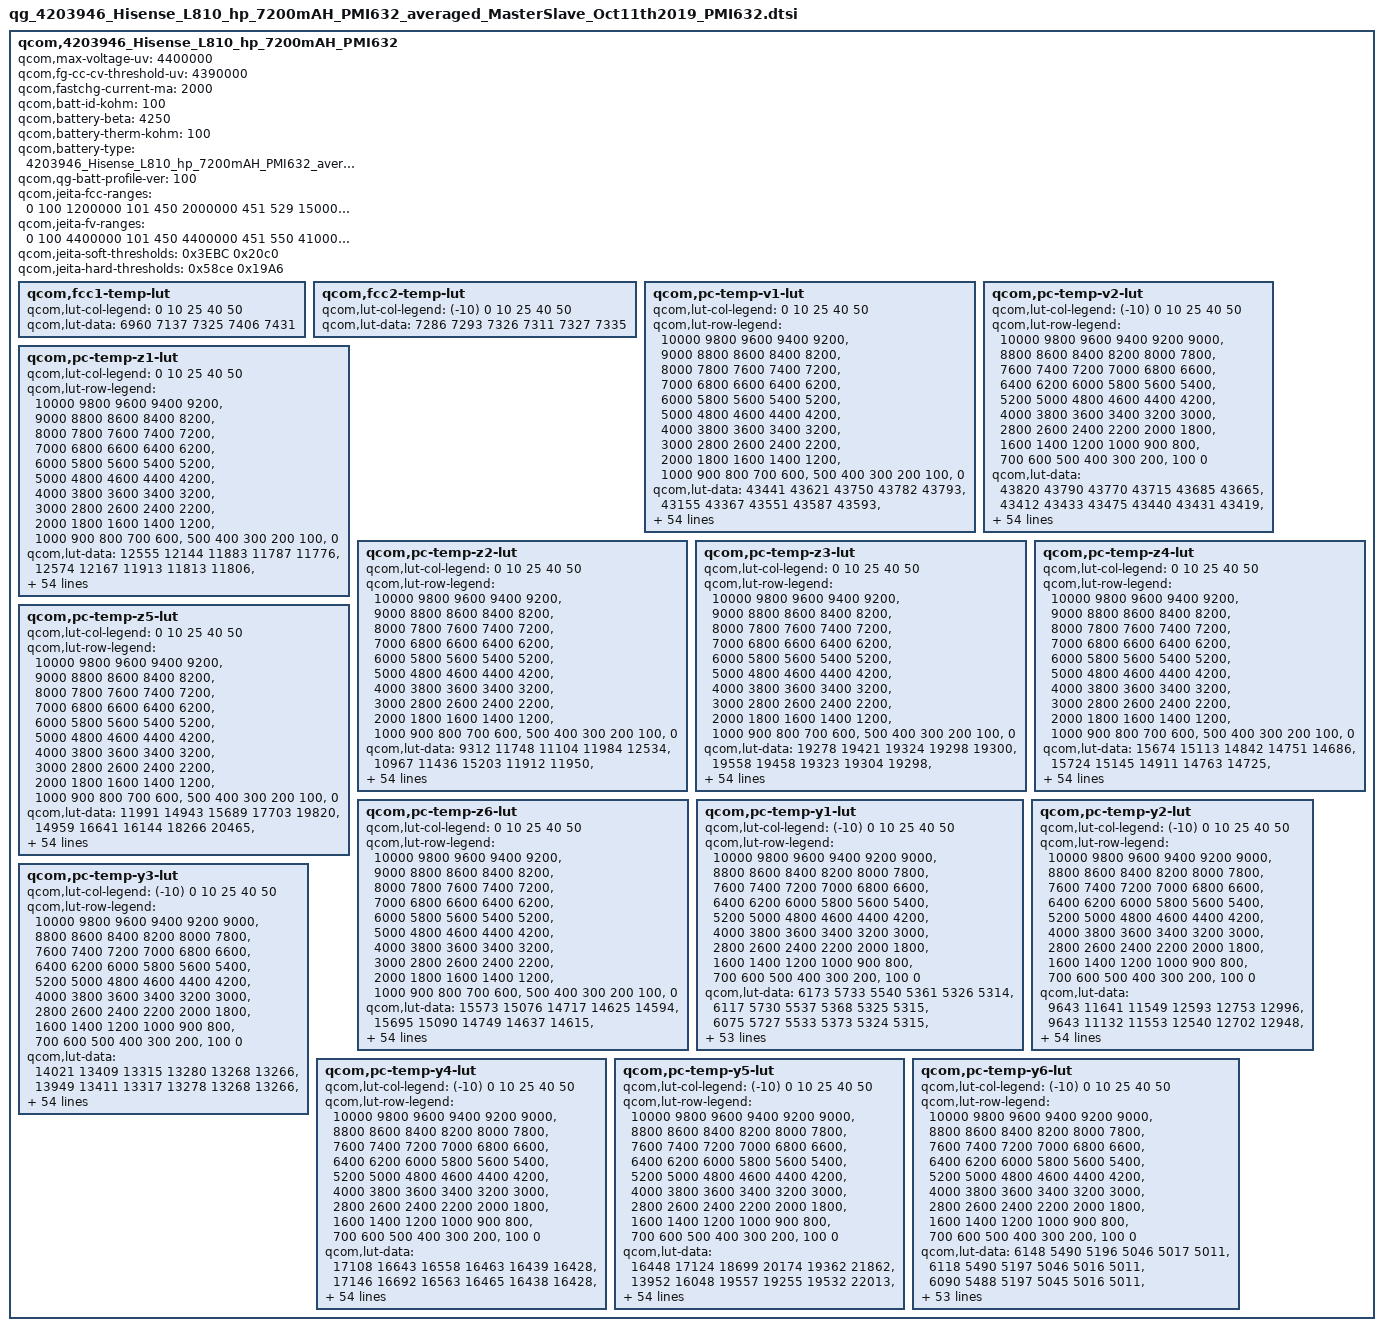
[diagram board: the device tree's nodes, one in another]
qcom,4203946_Hisense_L810_hp_7200mAH_PMI632 {
    /* 4203946_Hisense_L810_hp_7200mAH_PMI632_averaged_MasterSlave_Oct11th2019 */
    qcom,max-voltage-uv = <4400000>;
    qcom,fg-cc-cv-threshold-uv = <4390000>;
    qcom,fastchg-current-ma = <2000>;
    qcom,batt-id-kohm = <100>;
    qcom,battery-beta = <4250>;
    qcom,battery-therm-kohm = <100>;
    qcom,battery-type = "4203946_Hisense_L810_hp_7200mAH_PMI632_averaged_MasterSlave_Oct11th2019";
    qcom,qg-batt-profile-ver = <100>;

	qcom,jeita-fcc-ranges = <0  100   1200000
				 101 450  2000000
				 451 529  1500000>;
	qcom,jeita-fv-ranges =  <0  100  4400000
				 101 450  4400000
				 451 550  4100000>;
	/* COOL = 10 DegC, WARM = 45 DegC */
	qcom,jeita-soft-thresholds = <0x3EBC 0x20c0>;
	/* COLD = 0 DegC, HOT = 53 DegC */
	qcom,jeita-hard-thresholds = <0x58ce 0x19A6>;
	qcom,fcc1-temp-lut {
		qcom,lut-col-legend = <0 10 25 40 50>;
		qcom,lut-data = <6960 7137 7325 7406 7431>;
	};

	qcom,fcc2-temp-lut {
		qcom,lut-col-legend = <(-10) 0 10 25 40 50>;
		qcom,lut-data = <7286 7293 7326 7311 7327 7335>;
	};

	qcom,pc-temp-v1-lut {
		qcom,lut-col-legend = <0 10 25 40 50>;
		qcom,lut-row-legend = <10000 9800 9600 9400 9200>,
			<9000 8800 8600 8400 8200>,
			<8000 7800 7600 7400 7200>,
			<7000 6800 6600 6400 6200>,
			<6000 5800 5600 5400 5200>,
			<5000 4800 4600 4400 4200>,
			<4000 3800 3600 3400 3200>,
			<3000 2800 2600 2400 2200>,
			<2000 1800 1600 1400 1200>,
			<1000 900 800 700 600>,
			<500 400 300 200 100>,
			<0>;
		qcom,lut-data = <43441 43621 43750 43782 43793>,
			<43155 43367 43551 43587 43593>,
			<42911 43120 43325 43374 43386>,
			<42683 42882 43083 43147 43166>,
			<42459 42650 42845 42917 42941>,
			<42242 42424 42606 42684 42711>,
			<42030 42201 42372 42450 42478>,
			<41822 41985 42144 42216 42246>,
			<41620 41772 41919 41985 42015>,
			<41432 41564 41695 41756 41787>,
			<41272 41372 41473 41529 41562>,
			<41098 41207 41267 41308 41342>,
			<40859 41029 41088 41094 41123>,
			<40566 40786 40902 40887 40909>,
			<40305 40495 40657 40680 40702>,
			<40085 40251 40384 40472 40503>,
			<39896 40053 40176 40276 40311>,
			<39755 39887 40024 40100 40129>,
			<39645 39760 39882 39934 39954>,
			<39539 39656 39733 39765 39779>,
			<39425 39537 39578 39596 39607>,
			<39311 39391 39375 39408 39422>,
			<39199 39226 39092 39161 39193>,
			<39087 39029 38865 38926 38965>,
			<38979 38801 38741 38784 38810>,
			<38872 38640 38647 38681 38693>,
			<38767 38537 38563 38581 38584>,
			<38667 38461 38490 38480 38476>,
			<38568 38409 38419 38387 38377>,
			<38479 38371 38345 38301 38290>,
			<38414 38334 38276 38224 38212>,
			<38362 38298 38215 38156 38141>,
			<38317 38263 38161 38099 38078>,
			<38279 38229 38113 38043 38017>,
			<38245 38197 38072 37992 37960>,
			<38209 38161 38033 37942 37905>,
			<38174 38121 37993 37890 37843>,
			<38132 38075 37952 37839 37774>,
			<38072 38008 37894 37774 37698>,
			<37994 37910 37799 37686 37613>,
			<37904 37798 37685 37579 37516>,
			<37794 37672 37563 37462 37401>,
			<37663 37532 37426 37327 37266>,
			<37501 37375 37267 37170 37112>,
			<37354 37244 37135 37039 36979>,
			<37255 37171 37061 36970 36911>,
			<37220 37145 37045 36954 36894>,
			<37194 37126 37028 36941 36881>,
			<37165 37102 37015 36921 36861>,
			<37093 37037 36941 36835 36767>,
			<36814 36742 36647 36530 36458>,
			<36356 36291 36199 36078 36010>,
			<35774 35708 35619 35493 35431>,
			<34986 34919 34826 34697 34644>,
			<33744 33680 33595 33458 33433>,
			<30000 30000 30000 30000 30000>;
	};

	qcom,pc-temp-v2-lut {
		qcom,lut-col-legend = <(-10) 0 10 25 40 50>;
		qcom,lut-row-legend = <10000 9800 9600 9400 9200 9000>,
			<8800 8600 8400 8200 8000 7800>,
			<7600 7400 7200 7000 6800 6600>,
			<6400 6200 6000 5800 5600 5400>,
			<5200 5000 4800 4600 4400 4200>,
			<4000 3800 3600 3400 3200 3000>,
			<2800 2600 2400 2200 2000 1800>,
			<1600 1400 1200 1000 900 800>,
			<700 600 500 400 300 200>,
			<100 0>;
		qcom,lut-data = <43820 43790 43770 43715 43685 43665>,
			<43412 43433 43475 43440 43431 43419>,
			<43044 43106 43198 43178 43183 43178>,
			<42719 42813 42937 42929 42943 42941>,
			<42431 42548 42693 42693 42709 42709>,
			<42172 42299 42455 42461 42477 42477>,
			<41942 42065 42220 42230 42246 42245>,
			<41730 41838 41990 42002 42017 42015>,
			<41516 41598 41767 41780 41790 41794>,
			<41297 41344 41549 41561 41566 41580>,
			<41132 41152 41339 41344 41346 41366>,
			<41044 41048 41137 41126 41130 41148>,
			<40954 40947 40940 40912 40919 40934>,
			<40668 40725 40751 40719 40716 40729>,
			<40057 40339 40566 40538 40518 40529>,
			<39633 40013 40344 40339 40326 40335>,
			<39446 39783 40039 40101 40136 40148>,
			<39299 39582 39744 39874 39952 39965>,
			<39128 39391 39546 39712 39780 39793>,
			<38952 39211 39385 39578 39613 39624>,
			<38785 39031 39214 39406 39416 39426>,
			<38614 38845 39023 39152 39163 39174>,
			<38468 38670 38846 38910 38931 38946>,
			<38366 38508 38698 38749 38770 38786>,
			<38287 38357 38565 38618 38637 38652>,
			<38218 38246 38447 38501 38518 38531>,
			<38158 38163 38341 38396 38412 38423>,
			<38103 38097 38243 38301 38315 38324>,
			<38049 38042 38153 38213 38225 38233>,
			<37998 37997 38070 38131 38143 38148>,
			<37948 37952 37992 38055 38070 38071>,
			<37900 37908 37915 37983 38001 37999>,
			<37850 37865 37852 37914 37935 37930>,
			<37796 37822 37808 37850 37870 37867>,
			<37740 37779 37770 37788 37803 37802>,
			<37680 37731 37728 37728 37719 37708>,
			<37616 37679 37683 37670 37616 37582>,
			<37548 37621 37634 37607 37519 37470>,
			<37478 37552 37578 37536 37439 37383>,
			<37406 37475 37512 37458 37360 37300>,
			<37333 37386 37431 37370 37274 37214>,
			<37259 37284 37327 37269 37180 37122>,
			<37185 37177 37195 37156 37069 37011>,
			<37113 37070 37059 37026 36936 36876>,
			<37030 36972 36954 36901 36830 36776>,
			<36936 36882 36887 36871 36809 36755>,
			<36879 36832 36859 36860 36798 36742>,
			<36812 36774 36824 36841 36778 36724>,
			<36731 36700 36767 36806 36735 36683>,
			<36595 36588 36657 36692 36586 36522>,
			<36366 36363 36396 36374 36216 36155>,
			<35982 35965 35927 35874 35705 35646>,
			<35410 35362 35293 35233 35038 34986>,
			<34562 34526 34415 34363 34096 34062>,
			<33209 33189 33050 32998 32752 32744>,
			<28901 27920 27872 28105 28114 28828>;
	};

	qcom,pc-temp-z1-lut {
		qcom,lut-col-legend = <0 10 25 40 50>;
		qcom,lut-row-legend = <10000 9800 9600 9400 9200>,
			<9000 8800 8600 8400 8200>,
			<8000 7800 7600 7400 7200>,
			<7000 6800 6600 6400 6200>,
			<6000 5800 5600 5400 5200>,
			<5000 4800 4600 4400 4200>,
			<4000 3800 3600 3400 3200>,
			<3000 2800 2600 2400 2200>,
			<2000 1800 1600 1400 1200>,
			<1000 900 800 700 600>,
			<500 400 300 200 100>,
			<0>;
		qcom,lut-data = <12555 12144 11883 11787 11776>,
			<12574 12167 11913 11813 11806>,
			<12597 12180 11921 11823 11816>,
			<12618 12184 11925 11826 11820>,
			<12618 12187 11925 11828 11824>,
			<12604 12190 11924 11831 11827>,
			<12596 12198 11925 11833 11831>,
			<12599 12204 11926 11836 11836>,
			<12602 12203 11929 11840 11840>,
			<12607 12198 11931 11843 11846>,
			<12618 12198 11935 11849 11853>,
			<12626 12207 11939 11854 11860>,
			<12619 12214 11947 11859 11864>,
			<12595 12210 11953 11862 11867>,
			<12580 12198 11948 11863 11868>,
			<12581 12191 11938 11861 11868>,
			<12586 12187 11935 11860 11868>,
			<12587 12185 11939 11861 11869>,
			<12587 12189 11943 11862 11870>,
			<12587 12197 11946 11863 11871>,
			<12593 12200 11949 11865 11871>,
			<12601 12202 11951 11866 11872>,
			<12606 12204 11954 11867 11872>,
			<12606 12204 11956 11867 11873>,
			<12605 12204 11957 11869 11874>,
			<12598 12204 11959 11870 11876>,
			<12586 12204 11960 11873 11878>,
			<12581 12205 11963 11875 11880>,
			<12580 12207 11965 11878 11882>,
			<12581 12212 11969 11880 11883>,
			<12580 12215 11973 11882 11885>,
			<12578 12214 11975 11883 11886>,
			<12578 12214 11975 11885 11888>,
			<12593 12215 11976 11887 11890>,
			<12613 12219 11980 11889 11891>,
			<12615 12225 11984 11891 11892>,
			<12607 12239 11986 11892 11894>,
			<12601 12253 11987 11894 11895>,
			<12601 12254 11989 11896 11896>,
			<12602 12250 11993 11897 11898>,
			<12604 12247 11997 11898 11899>,
			<12603 12246 11997 11901 11900>,
			<12610 12249 11995 11904 11902>,
			<12630 12264 11998 11905 11903>,
			<12633 12266 12003 11907 11904>,
			<12624 12252 12007 11910 11905>,
			<12620 12247 12003 11909 11906>,
			<12640 12263 12000 11911 11906>,
			<12595 12259 12008 11914 11908>,
			<12615 12247 12003 11916 11910>,
			<12620 12262 12011 11918 11912>,
			<12625 12266 12014 11921 11916>,
			<12633 12272 12025 11928 11921>,
			<12656 12322 12033 11937 11929>,
			<12656 12322 12033 11937 11929>,
			<12656 12322 12033 11937 11929>;
	};

	qcom,pc-temp-z2-lut {
		qcom,lut-col-legend = <0 10 25 40 50>;
		qcom,lut-row-legend = <10000 9800 9600 9400 9200>,
			<9000 8800 8600 8400 8200>,
			<8000 7800 7600 7400 7200>,
			<7000 6800 6600 6400 6200>,
			<6000 5800 5600 5400 5200>,
			<5000 4800 4600 4400 4200>,
			<4000 3800 3600 3400 3200>,
			<3000 2800 2600 2400 2200>,
			<2000 1800 1600 1400 1200>,
			<1000 900 800 700 600>,
			<500 400 300 200 100>,
			<0>;
		qcom,lut-data = <9312 11748 11104 11984 12534>,
			<10967 11436 15203 11912 11950>,
			<11025 11278 14279 12211 12062>,
			<11051 11257 13166 13397 12060>,
			<11082 11233 12801 13872 12079>,
			<11113 11208 12586 13539 12702>,
			<11138 11184 12364 13147 13532>,
			<11162 11161 12076 12987 13595>,
			<11182 11139 11887 12883 13421>,
			<11187 11120 11915 12823 13257>,
			<11182 11117 12006 12777 13067>,
			<11171 11132 12046 12728 12918>,
			<11100 11147 12057 12655 12919>,
			<10940 11130 12070 12569 12952>,
			<10866 11090 12129 12558 12911>,
			<10863 11079 12224 12633 12401>,
			<10864 11116 12217 12683 12006>,
			<10875 11174 11960 12346 12021>,
			<10907 11242 11776 11907 12045>,
			<10925 11323 11769 11893 12064>,
			<10915 11350 11759 12057 12096>,
			<10897 11341 11734 12141 12112>,
			<10887 11325 11671 12005 12074>,
			<10878 11306 11633 11841 12022>,
			<10874 11282 11633 11843 12060>,
			<10878 11274 11636 11911 12218>,
			<10888 11306 11674 11996 12287>,
			<10899 11346 11826 12132 12269>,
			<10915 11358 11909 12227 12230>,
			<10932 11364 11864 12159 12087>,
			<10944 11368 11804 12015 11825>,
			<10953 11371 11788 11984 11751>,
			<10964 11375 11782 12028 11770>,
			<10976 11381 11781 12091 11804>,
			<10991 11393 11808 12174 11895>,
			<11013 11404 11848 12274 12057>,
			<11047 11412 11879 12355 12261>,
			<11078 11422 11909 12427 12582>,
			<11103 11438 11950 12492 12733>,
			<11124 11468 12022 12565 12725>,
			<11070 11490 12076 12616 12706>,
			<10502 11497 12075 12597 12620>,
			<10163 11506 12064 12545 12448>,
			<10078 11532 12076 12550 12371>,
			<10489 11706 12155 12550 12344>,
			<10774 11960 12212 12361 12420>,
			<10928 11844 12182 12326 12319>,
			<10767 11717 12132 12269 12324>,
			<10818 11856 12228 12311 12489>,
			<10975 11847 12355 12614 12569>,
			<10719 11762 12439 12532 12181>,
			<10352 11553 12416 12358 12002>,
			<9961 11353 12444 12201 11921>,
			<9733 11108 12268 12014 11772>,
			<9733 11108 12268 12014 11772>,
			<9733 11108 12268 12014 11772>;
	};

	qcom,pc-temp-z3-lut {
		qcom,lut-col-legend = <0 10 25 40 50>;
		qcom,lut-row-legend = <10000 9800 9600 9400 9200>,
			<9000 8800 8600 8400 8200>,
			<8000 7800 7600 7400 7200>,
			<7000 6800 6600 6400 6200>,
			<6000 5800 5600 5400 5200>,
			<5000 4800 4600 4400 4200>,
			<4000 3800 3600 3400 3200>,
			<3000 2800 2600 2400 2200>,
			<2000 1800 1600 1400 1200>,
			<1000 900 800 700 600>,
			<500 400 300 200 100>,
			<0>;
		qcom,lut-data = <19278 19421 19324 19298 19300>,
			<19558 19458 19323 19304 19298>,
			<19596 19482 19342 19317 19306>,
			<19613 19491 19363 19325 19310>,
			<19613 19500 19376 19330 19312>,
			<19601 19501 19386 19334 19318>,
			<19590 19499 19394 19338 19325>,
			<19583 19496 19400 19341 19328>,
			<19574 19494 19403 19343 19330>,
			<19565 19492 19401 19345 19330>,
			<19553 19488 19395 19345 19325>,
			<19544 19476 19392 19345 19320>,
			<19564 19465 19391 19339 19319>,
			<19617 19471 19390 19330 19318>,
			<19640 19485 19388 19328 19316>,
			<19629 19489 19385 19329 19306>,
			<19610 19477 19379 19330 19298>,
			<19590 19459 19362 19322 19297>,
			<19562 19442 19350 19312 19296>,
			<19548 19424 19352 19311 19297>,
			<19550 19420 19357 19315 19300>,
			<19555 19436 19362 19318 19303>,
			<19559 19456 19370 19318 19300>,
			<19565 19465 19374 19317 19297>,
			<19570 19472 19369 19313 19297>,
			<19573 19474 19362 19307 19298>,
			<19577 19474 19359 19305 19300>,
			<19582 19473 19357 19320 19314>,
			<19587 19471 19356 19334 19327>,
			<19590 19466 19367 19336 19324>,
			<19588 19461 19380 19337 19316>,
			<19580 19457 19381 19336 19312>,
			<19570 19453 19379 19332 19311>,
			<19559 19450 19376 19328 19310>,
			<19547 19447 19372 19325 19307>,
			<19535 19446 19369 19323 19305>,
			<19519 19445 19366 19322 19305>,
			<19508 19445 19365 19322 19307>,
			<19503 19444 19363 19321 19308>,
			<19500 19442 19361 19321 19308>,
			<19477 19441 19360 19320 19306>,
			<19329 19438 19358 19317 19304>,
			<19263 19435 19356 19314 19300>,
			<19264 19427 19355 19315 19300>,
			<19261 19404 19349 19314 19301>,
			<19260 19354 19341 19307 19296>,
			<19259 19329 19334 19302 19294>,
			<19260 19304 19335 19301 19293>,
			<19260 19296 19305 19300 19290>,
			<19259 19295 19321 19292 19290>,
			<19260 19309 19305 19293 19298>,
			<19261 19306 19304 19297 19299>,
			<19264 19307 19294 19301 19300>,
			<19267 19301 19295 19303 19306>,
			<19267 19301 19295 19303 19306>,
			<19267 19301 19295 19303 19306>;
	};

	qcom,pc-temp-z4-lut {
		qcom,lut-col-legend = <0 10 25 40 50>;
		qcom,lut-row-legend = <10000 9800 9600 9400 9200>,
			<9000 8800 8600 8400 8200>,
			<8000 7800 7600 7400 7200>,
			<7000 6800 6600 6400 6200>,
			<6000 5800 5600 5400 5200>,
			<5000 4800 4600 4400 4200>,
			<4000 3800 3600 3400 3200>,
			<3000 2800 2600 2400 2200>,
			<2000 1800 1600 1400 1200>,
			<1000 900 800 700 600>,
			<500 400 300 200 100>,
			<0>;
		qcom,lut-data = <15674 15113 14842 14751 14686>,
			<15724 15145 14911 14763 14725>,
			<15641 15143 14893 14780 14744>,
			<15501 15092 14860 14765 14737>,
			<15400 15008 14829 14749 14728>,
			<15318 14947 14795 14733 14713>,
			<15249 14903 14765 14717 14696>,
			<15193 14866 14735 14703 14682>,
			<15146 14834 14713 14689 14671>,
			<15105 14808 14702 14676 14663>,
			<15071 14788 14695 14663 14658>,
			<15038 14774 14686 14654 14653>,
			<14994 14763 14671 14652 14646>,
			<14945 14752 14660 14650 14638>,
			<14911 14743 14660 14647 14634>,
			<14891 14733 14661 14639 14639>,
			<14877 14724 14662 14633 14642>,
			<14866 14717 14661 14634 14638>,
			<14855 14714 14659 14637 14632>,
			<14844 14712 14656 14638 14631>,
			<14824 14708 14653 14638 14632>,
			<14801 14696 14662 14641 14635>,
			<14783 14684 14723 14685 14672>,
			<14768 14701 14763 14736 14720>,
			<14756 14751 14763 14739 14724>,
			<14746 14772 14762 14737 14716>,
			<14738 14771 14758 14731 14704>,
			<14734 14767 14746 14706 14679>,
			<14733 14759 14729 14678 14655>,
			<14732 14743 14705 14664 14650>,
			<14732 14729 14682 14654 14647>,
			<14732 14718 14672 14648 14644>,
			<14732 14709 14667 14644 14638>,
			<14733 14700 14665 14642 14634>,
			<14734 14693 14664 14644 14636>,
			<14736 14687 14664 14647 14640>,
			<14741 14682 14664 14650 14645>,
			<14744 14679 14665 14654 14652>,
			<14742 14680 14666 14658 14655>,
			<14738 14684 14673 14661 14655>,
			<14753 14686 14678 14663 14655>,
			<14906 14684 14677 14662 14654>,
			<14974 14682 14673 14661 14653>,
			<14957 14682 14672 14661 14655>,
			<14889 14674 14664 14659 14654>,
			<14868 14692 14643 14643 14639>,
			<14865 14715 14639 14637 14632>,
			<14860 14738 14630 14626 14619>,
			<14855 14742 14656 14620 14615>,
			<14849 14741 14643 14637 14625>,
			<14856 14737 14675 14647 14625>,
			<14867 14748 14680 14645 14626>,
			<14877 14752 14692 14642 14625>,
			<14888 14764 14693 14640 14620>,
			<14888 14764 14693 14640 14620>,
			<14888 14764 14693 14640 14620>;
	};

	qcom,pc-temp-z5-lut {
		qcom,lut-col-legend = <0 10 25 40 50>;
		qcom,lut-row-legend = <10000 9800 9600 9400 9200>,
			<9000 8800 8600 8400 8200>,
			<8000 7800 7600 7400 7200>,
			<7000 6800 6600 6400 6200>,
			<6000 5800 5600 5400 5200>,
			<5000 4800 4600 4400 4200>,
			<4000 3800 3600 3400 3200>,
			<3000 2800 2600 2400 2200>,
			<2000 1800 1600 1400 1200>,
			<1000 900 800 700 600>,
			<500 400 300 200 100>,
			<0>;
		qcom,lut-data = <11991 14943 15689 17703 19820>,
			<14959 16641 16144 18266 20465>,
			<15705 17960 17236 19821 21911>,
			<16102 18847 18542 20999 22267>,
			<16250 19559 19802 21689 22637>,
			<16344 20086 21194 22292 23861>,
			<16388 20453 22508 23157 25646>,
			<16467 20836 23744 24207 27252>,
			<16583 21592 24956 25777 29132>,
			<16589 22603 26074 27728 29939>,
			<16494 22940 27162 30640 29370>,
			<16411 22582 28814 32424 28661>,
			<17519 22223 32040 31657 30251>,
			<20535 24531 34516 29983 34085>,
			<21911 29968 35035 30112 34679>,
			<21423 31805 35163 33639 28770>,
			<20682 29835 34219 36228 24087>,
			<20102 27204 29843 33202 24571>,
			<19093 25262 26654 29083 26112>,
			<18573 23399 29661 30584 28820>,
			<19197 23285 36956 36831 34759>,
			<20561 32522 44303 40023 38050>,
			<22096 45596 54317 37927 33694>,
			<24048 55773 59538 34283 26681>,
			<26401 65535 51394 29500 22867>,
			<29432 65535 37599 22351 20102>,
			<33487 64503 30959 20186 19467>,
			<37914 57847 26833 22287 24790>,
			<43885 52150 25382 25604 30209>,
			<48417 46354 29461 29628 30307>,
			<47929 42647 36392 34594 29866>,
			<44366 40429 42035 38668 30259>,
			<40622 39103 47511 42125 34724>,
			<36986 39110 50695 45013 39063>,
			<33221 39690 52348 47708 40889>,
			<30135 40538 53240 49721 42086>,
			<27012 42675 52803 49447 42167>,
			<25100 45174 51033 46729 41562>,
			<24971 46337 48762 43482 40554>,
			<25168 47143 45097 39714 37463>,
			<23991 47418 41541 35833 33261>,
			<15842 46187 39530 32820 30213>,
			<12218 44143 38059 30461 27739>,
			<12295 39681 36393 29442 25961>,
			<12675 35444 36425 28715 25807>,
			<12655 21662 38132 28802 26337>,
			<12607 17752 33168 27579 26833>,
			<12540 15081 35600 29742 31752>,
			<12522 14507 19996 32359 32809>,
			<12622 14576 25821 22902 25347>,
			<12813 15787 18590 19338 25331>,
			<12678 15132 17497 19682 24556>,
			<12565 14882 15830 20384 24833>,
			<12413 14099 15653 20815 28558>,
			<12413 14099 15653 20815 28558>,
			<12413 14099 15653 20815 28558>;
	};

	qcom,pc-temp-z6-lut {
		qcom,lut-col-legend = <0 10 25 40 50>;
		qcom,lut-row-legend = <10000 9800 9600 9400 9200>,
			<9000 8800 8600 8400 8200>,
			<8000 7800 7600 7400 7200>,
			<7000 6800 6600 6400 6200>,
			<6000 5800 5600 5400 5200>,
			<5000 4800 4600 4400 4200>,
			<4000 3800 3600 3400 3200>,
			<3000 2800 2600 2400 2200>,
			<2000 1800 1600 1400 1200>,
			<1000 900 800 700 600>,
			<500 400 300 200 100>,
			<0>;
		qcom,lut-data = <15573 15076 14717 14625 14594>,
			<15695 15090 14749 14637 14615>,
			<15650 15093 14748 14651 14628>,
			<15571 15072 14745 14650 14628>,
			<15505 15027 14739 14649 14627>,
			<15443 14990 14728 14645 14625>,
			<15390 14962 14717 14640 14622>,
			<15349 14937 14706 14635 14619>,
			<15314 14918 14697 14631 14616>,
			<15282 14901 14691 14627 14613>,
			<15250 14885 14686 14623 14610>,
			<15225 14868 14681 14619 14607>,
			<15210 14855 14675 14615 14604>,
			<15200 14849 14670 14611 14600>,
			<15187 14844 14666 14608 14597>,
			<15167 14837 14664 14605 14594>,
			<15144 14825 14659 14602 14591>,
			<15125 14813 14651 14598 14588>,
			<15108 14804 14645 14594 14585>,
			<15094 14796 14646 14594 14585>,
			<15085 14794 14647 14596 14587>,
			<15078 14798 14655 14600 14590>,
			<15073 14805 14685 14620 14606>,
			<15069 14819 14705 14640 14624>,
			<15067 14844 14703 14641 14626>,
			<15066 14854 14700 14637 14624>,
			<15064 14854 14697 14634 14621>,
			<15065 14854 14691 14631 14618>,
			<15069 14851 14686 14627 14615>,
			<15073 14843 14682 14623 14611>,
			<15073 14835 14679 14620 14606>,
			<15070 14830 14676 14616 14602>,
			<15067 14824 14674 14612 14598>,
			<15063 14821 14671 14610 14596>,
			<15060 14818 14670 14610 14597>,
			<15057 14817 14669 14610 14597>,
			<15054 14817 14669 14611 14598>,
			<15053 14817 14669 14612 14603>,
			<15053 14819 14669 14614 14605>,
			<15053 14822 14672 14615 14605>,
			<15053 14825 14675 14616 14604>,
			<15050 14826 14675 14615 14603>,
			<15047 14826 14673 14613 14601>,
			<15045 14825 14673 14614 14602>,
			<15024 14815 14669 14613 14602>,
			<15015 14801 14657 14603 14593>,
			<15016 14799 14653 14598 14589>,
			<15012 14796 14649 14592 14583>,
			<15011 14796 14646 14589 14580>,
			<15014 14798 14649 14593 14584>,
			<15024 14807 14657 14600 14590>,
			<15034 14814 14660 14602 14591>,
			<15049 14822 14663 14604 14593>,
			<15067 14833 14668 14606 14595>,
			<15067 14833 14668 14606 14595>,
			<15067 14833 14668 14606 14595>;
	};

	qcom,pc-temp-y1-lut {
		qcom,lut-col-legend = <(-10) 0 10 25 40 50>;
		qcom,lut-row-legend = <10000 9800 9600 9400 9200 9000>,
			<8800 8600 8400 8200 8000 7800>,
			<7600 7400 7200 7000 6800 6600>,
			<6400 6200 6000 5800 5600 5400>,
			<5200 5000 4800 4600 4400 4200>,
			<4000 3800 3600 3400 3200 3000>,
			<2800 2600 2400 2200 2000 1800>,
			<1600 1400 1200 1000 900 800>,
			<700 600 500 400 300 200>,
			<100 0>;
		qcom,lut-data = <6173 5733 5540 5361 5326 5314>,
			<6117 5730 5537 5368 5325 5315>,
			<6075 5727 5533 5373 5324 5315>,
			<6046 5725 5529 5377 5323 5314>,
			<6029 5724 5525 5379 5322 5314>,
			<6025 5723 5524 5380 5320 5314>,
			<6040 5724 5523 5379 5320 5313>,
			<6061 5726 5523 5377 5319 5312>,
			<6063 5725 5524 5377 5318 5311>,
			<6061 5723 5528 5374 5317 5311>,
			<6059 5722 5530 5373 5316 5311>,
			<6052 5729 5531 5374 5316 5311>,
			<6042 5739 5532 5374 5316 5311>,
			<6041 5744 5532 5374 5315 5311>,
			<6049 5749 5532 5373 5314 5311>,
			<6052 5752 5532 5373 5314 5311>,
			<6044 5760 5535 5375 5314 5311>,
			<6036 5767 5537 5377 5315 5311>,
			<6038 5765 5536 5377 5315 5311>,
			<6042 5760 5534 5376 5316 5311>,
			<6044 5756 5533 5375 5316 5312>,
			<6042 5750 5529 5375 5316 5312>,
			<6040 5744 5526 5375 5316 5312>,
			<6039 5748 5531 5377 5316 5313>,
			<6040 5757 5540 5381 5317 5313>,
			<6040 5759 5541 5382 5318 5314>,
			<6040 5751 5535 5381 5318 5314>,
			<6041 5744 5531 5381 5319 5314>,
			<6041 5744 5531 5382 5320 5315>,
			<6039 5746 5533 5384 5321 5316>,
			<6037 5745 5536 5386 5323 5317>,
			<6033 5740 5544 5387 5324 5319>,
			<6031 5736 5548 5388 5325 5320>,
			<6038 5740 5542 5390 5326 5321>,
			<6055 5747 5535 5391 5328 5321>,
			<6059 5752 5535 5392 5329 5322>,
			<6048 5757 5538 5392 5331 5323>,
			<6037 5761 5542 5393 5332 5324>,
			<6031 5755 5548 5396 5334 5325>,
			<6027 5746 5553 5400 5335 5327>,
			<6025 5747 5553 5402 5336 5328>,
			<6025 5758 5548 5404 5337 5329>,
			<6026 5756 5546 5406 5338 5330>,
			<6030 5750 5542 5408 5340 5331>,
			<6040 5761 5542 5407 5341 5332>,
			<6036 5759 5545 5407 5344 5333>,
			<6032 5760 5541 5410 5343 5333>,
			<6047 5777 5550 5408 5346 5334>,
			<6072 5762 5549 5412 5344 5334>,
			<6063 5767 5556 5415 5345 5335>,
			<6051 5773 5550 5414 5348 5337>,
			<6054 5773 5563 5416 5350 5339>,
			<6077 5777 5567 5425 5354 5342>,
			<6079 5782 5584 5431 5360 5348>,
			<6079 5782 5584 5431 5360 5348>,
			<6079 5782 5584 5431 5360 5348>;
	};

	qcom,pc-temp-y2-lut {
		qcom,lut-col-legend = <(-10) 0 10 25 40 50>;
		qcom,lut-row-legend = <10000 9800 9600 9400 9200 9000>,
			<8800 8600 8400 8200 8000 7800>,
			<7600 7400 7200 7000 6800 6600>,
			<6400 6200 6000 5800 5600 5400>,
			<5200 5000 4800 4600 4400 4200>,
			<4000 3800 3600 3400 3200 3000>,
			<2800 2600 2400 2200 2000 1800>,
			<1600 1400 1200 1000 900 800>,
			<700 600 500 400 300 200>,
			<100 0>;
		qcom,lut-data = <9643 11641 11549 12593 12753 12996>,
			<9643 11132 11553 12540 12702 12948>,
			<9643 10756 11552 12459 12615 12867>,
			<9771 10501 11545 12372 12519 12777>,
			<9928 10359 11536 12304 12443 12704>,
			<10097 10320 11524 12278 12415 12672>,
			<10331 10451 11503 12283 12419 12635>,
			<10531 10638 11483 12291 12425 12581>,
			<10432 10709 11485 12284 12426 12537>,
			<9937 10789 11500 12258 12421 12496>,
			<9682 10885 11506 12238 12419 12477>,
			<9684 11047 11494 12229 12467 12440>,
			<9687 11192 11481 12225 12520 12405>,
			<9685 11216 11568 12228 12525 12462>,
			<9679 11218 11816 12237 12525 12611>,
			<9675 11230 11907 12252 12536 12658>,
			<9674 11314 11860 12300 12601 12570>,
			<9673 11425 11815 12370 12694 12490>,
			<9673 11501 11827 12465 12828 12627>,
			<9672 11566 11865 12586 13005 12932>,
			<9672 11567 11904 12619 13039 13009>,
			<9671 11142 11950 12570 12883 12922>,
			<9671 10753 12004 12525 12758 12848>,
			<9670 10528 12070 12541 12792 12855>,
			<9670 9974 12141 12593 12857 12881>,
			<9669 9772 12187 12646 12870 12898>,
			<9668 9765 12218 12720 12878 12980>,
			<9668 9756 12240 12773 12900 13064>,
			<9667 9744 12256 12789 12982 13121>,
			<9666 9728 12272 12797 13101 13169>,
			<9666 9716 12292 12796 13169 13178>,
			<9665 9708 12321 12790 13272 13156>,
			<9665 9701 12335 12784 13319 13162>,
			<9665 9695 12289 12738 13261 13237>,
			<9664 9689 12189 12678 13191 13310>,
			<9664 9684 11912 12682 13168 13290>,
			<9664 9680 11295 12731 13103 13189>,
			<9664 9676 11042 12757 13065 13118>,
			<9663 9673 11407 12768 13027 13074>,
			<9663 9670 11774 12778 12993 13040>,
			<9663 9668 11731 12739 13032 13082>,
			<9663 9666 11595 12636 13087 13193>,
			<9663 9665 10985 12614 13130 13270>,
			<9662 9664 10209 12592 13157 13247>,
			<9662 9663 9976 12421 12926 12947>,
			<9662 9663 9852 12316 12871 12976>,
			<9662 9662 9801 12328 12868 12965>,
			<9662 9662 9754 12365 12840 12842>,
			<9662 9662 9741 12290 12794 12707>,
			<9662 9662 9746 12226 12802 12580>,
			<9662 9661 9727 12118 12819 12606>,
			<9662 9661 9707 11989 12610 12428>,
			<9661 9661 9688 11814 12365 12295>,
			<9660 9660 9677 11664 12192 12085>,
			<9660 9660 9677 11664 12192 12085>,
			<9660 9660 9677 11664 12192 12085>;
	};

	qcom,pc-temp-y3-lut {
		qcom,lut-col-legend = <(-10) 0 10 25 40 50>;
		qcom,lut-row-legend = <10000 9800 9600 9400 9200 9000>,
			<8800 8600 8400 8200 8000 7800>,
			<7600 7400 7200 7000 6800 6600>,
			<6400 6200 6000 5800 5600 5400>,
			<5200 5000 4800 4600 4400 4200>,
			<4000 3800 3600 3400 3200 3000>,
			<2800 2600 2400 2200 2000 1800>,
			<1600 1400 1200 1000 900 800>,
			<700 600 500 400 300 200>,
			<100 0>;
		qcom,lut-data = <14021 13409 13315 13280 13268 13266>,
			<13949 13411 13317 13278 13268 13266>,
			<13858 13410 13319 13277 13268 13267>,
			<13769 13408 13322 13276 13269 13267>,
			<13702 13405 13323 13275 13269 13267>,
			<13677 13404 13325 13275 13269 13268>,
			<13691 13402 13326 13276 13270 13268>,
			<13709 13401 13327 13278 13270 13269>,
			<13683 13405 13328 13280 13270 13269>,
			<13571 13414 13328 13282 13270 13269>,
			<13513 13418 13329 13284 13270 13269>,
			<13535 13391 13329 13284 13272 13269>,
			<13561 13360 13329 13284 13274 13269>,
			<13550 13361 13329 13286 13274 13269>,
			<13502 13375 13329 13288 13273 13271>,
			<13472 13381 13328 13289 13273 13272>,
			<13463 13376 13324 13289 13274 13271>,
			<13458 13368 13320 13289 13276 13271>,
			<13461 13362 13317 13289 13278 13271>,
			<13469 13356 13315 13290 13279 13273>,
			<13472 13348 13312 13290 13279 13274>,
			<13467 13328 13308 13285 13275 13270>,
			<13463 13309 13304 13280 13271 13267>,
			<13467 13306 13301 13278 13270 13266>,
			<13482 13304 13297 13277 13268 13266>,
			<13498 13300 13296 13277 13268 13266>,
			<13516 13289 13296 13277 13268 13266>,
			<13536 13281 13295 13278 13268 13266>,
			<13558 13285 13295 13279 13268 13267>,
			<13582 13295 13295 13280 13270 13267>,
			<13608 13304 13294 13280 13270 13267>,
			<13637 13311 13289 13280 13271 13267>,
			<13668 13320 13286 13280 13271 13267>,
			<13699 13333 13289 13279 13271 13268>,
			<13731 13350 13293 13279 13271 13268>,
			<13767 13369 13294 13279 13271 13268>,
			<13805 13391 13293 13280 13270 13267>,
			<13846 13417 13293 13280 13269 13266>,
			<13886 13448 13299 13279 13268 13266>,
			<13928 13485 13304 13277 13268 13266>,
			<13970 13528 13306 13276 13268 13266>,
			<14011 13578 13307 13276 13268 13266>,
			<14058 13636 13302 13278 13269 13266>,
			<14107 13701 13299 13280 13270 13266>,
			<14139 13756 13307 13279 13268 13267>,
			<14139 13780 13318 13279 13269 13267>,
			<14181 13824 13325 13282 13272 13268>,
			<14227 13873 13336 13284 13272 13270>,
			<14281 13916 13350 13289 13274 13272>,
			<14337 13954 13365 13291 13276 13270>,
			<14394 13981 13375 13290 13270 13270>,
			<14460 14026 13379 13292 13275 13270>,
			<14550 14112 13406 13295 13278 13273>,
			<14686 14241 13459 13304 13279 13274>,
			<14686 14241 13459 13304 13279 13274>,
			<14686 14241 13459 13304 13279 13274>;
	};

	qcom,pc-temp-y4-lut {
		qcom,lut-col-legend = <(-10) 0 10 25 40 50>;
		qcom,lut-row-legend = <10000 9800 9600 9400 9200 9000>,
			<8800 8600 8400 8200 8000 7800>,
			<7600 7400 7200 7000 6800 6600>,
			<6400 6200 6000 5800 5600 5400>,
			<5200 5000 4800 4600 4400 4200>,
			<4000 3800 3600 3400 3200 3000>,
			<2800 2600 2400 2200 2000 1800>,
			<1600 1400 1200 1000 900 800>,
			<700 600 500 400 300 200>,
			<100 0>;
		qcom,lut-data = <17108 16643 16558 16463 16439 16428>,
			<17146 16692 16563 16465 16438 16428>,
			<17162 16745 16571 16468 16437 16428>,
			<17162 16796 16579 16471 16437 16428>,
			<17149 16834 16585 16473 16438 16428>,
			<17127 16854 16588 16475 16438 16428>,
			<17033 16858 16589 16476 16440 16429>,
			<16923 16856 16590 16476 16442 16430>,
			<17000 16844 16593 16477 16445 16432>,
			<17362 16823 16604 16479 16449 16434>,
			<17553 16817 16614 16482 16451 16437>,
			<17555 17000 16623 16487 16453 16441>,
			<17552 17221 16633 16495 16454 16445>,
			<17440 17177 16675 16504 16459 16448>,
			<17088 16953 16756 16515 16469 16450>,
			<16921 16814 16781 16526 16478 16454>,
			<16915 16769 16712 16535 16482 16461>,
			<16910 16740 16637 16546 16488 16471>,
			<16884 16719 16618 16562 16502 16482>,
			<16822 16704 16608 16583 16521 16494>,
			<16773 16692 16590 16584 16522 16494>,
			<16736 16680 16555 16525 16484 16467>,
			<16712 16670 16528 16470 16449 16443>,
			<16705 16648 16521 16462 16443 16437>,
			<16701 16612 16516 16458 16439 16433>,
			<16699 16602 16514 16457 16439 16433>,
			<16697 16609 16513 16459 16441 16434>,
			<16696 16614 16512 16461 16444 16436>,
			<16698 16613 16509 16464 16447 16439>,
			<16703 16611 16507 16468 16452 16444>,
			<16706 16611 16505 16472 16458 16449>,
			<16709 16617 16503 16478 16466 16456>,
			<16712 16623 16502 16481 16472 16462>,
			<16716 16629 16502 16482 16477 16467>,
			<16719 16635 16503 16482 16480 16470>,
			<16721 16641 16510 16481 16475 16465>,
			<16722 16647 16529 16474 16454 16447>,
			<16723 16652 16539 16468 16443 16437>,
			<16723 16657 16539 16463 16441 16435>,
			<16724 16661 16539 16460 16441 16434>,
			<16727 16661 16543 16461 16441 16435>,
			<16740 16657 16548 16467 16442 16436>,
			<16756 16656 16562 16471 16444 16438>,
			<16777 16657 16572 16473 16443 16435>,
			<16792 16665 16569 16462 16435 16427>,
			<16773 16675 16585 16474 16445 16437>,
			<16786 16703 16607 16484 16450 16441>,
			<16810 16729 16638 16498 16457 16447>,
			<16836 16768 16676 16517 16467 16456>,
			<16845 16808 16710 16522 16456 16446>,
			<16841 16827 16707 16504 16447 16433>,
			<16821 16821 16693 16501 16446 16435>,
			<16818 16814 16712 16520 16453 16441>,
			<16851 16834 16762 16559 16485 16468>,
			<16851 16834 16762 16559 16485 16468>,
			<16851 16834 16762 16559 16485 16468>;
	};

	qcom,pc-temp-y5-lut {
		qcom,lut-col-legend = <(-10) 0 10 25 40 50>;
		qcom,lut-row-legend = <10000 9800 9600 9400 9200 9000>,
			<8800 8600 8400 8200 8000 7800>,
			<7600 7400 7200 7000 6800 6600>,
			<6400 6200 6000 5800 5600 5400>,
			<5200 5000 4800 4600 4400 4200>,
			<4000 3800 3600 3400 3200 3000>,
			<2800 2600 2400 2200 2000 1800>,
			<1600 1400 1200 1000 900 800>,
			<700 600 500 400 300 200>,
			<100 0>;
		qcom,lut-data = <16448 17124 18699 20174 19362 21862>,
			<13952 16048 19557 19255 19532 22013>,
			<12864 15593 20215 18215 19531 22079>,
			<12877 15538 20678 17241 19396 22077>,
			<13684 15663 20947 16518 19163 22025>,
			<14995 15751 21025 16234 18869 21938>,
			<19267 16184 20806 16326 18461 21629>,
			<24095 16662 20426 16521 17966 21114>,
			<23051 16314 20058 16825 17411 20551>,
			<16358 15428 19507 17528 16770 19859>,
			<12984 15020 18900 17845 16560 19110>,
			<17226 15256 17760 17395 17476 18105>,
			<22409 15803 16781 16857 18481 17361>,
			<21333 17925 16954 16756 18014 17651>,
			<15862 23005 17860 16717 16505 18557>,
			<13379 25093 19081 16710 15966 18804>,
			<13690 23602 21345 16762 16479 17711>,
			<14209 22009 23321 16912 17302 16711>,
			<14799 22178 23931 18192 18232 17187>,
			<15504 22928 24291 21108 19412 18432>,
			<15664 23011 24304 22553 20700 19247>,
			<14336 20546 23606 22802 22390 19716>,
			<12961 18194 22615 22824 23416 20140>,
			<12785 17112 21381 22229 22550 20695>,
			<12756 14924 20085 20852 20710 21223>,
			<12775 13878 19832 20470 19821 21297>,
			<12925 13172 20006 20829 19349 20780>,
			<13047 12691 20274 21395 19265 20511>,
			<13054 12871 21045 22471 20024 20953>,
			<13097 13272 22080 23832 21250 21494>,
			<13181 13444 21716 24335 22189 21449>,
			<13344 13446 18923 24490 23027 20904>,
			<13490 13456 17276 24637 23860 20631>,
			<13567 13656 18480 24851 24893 22210>,
			<13612 13959 20175 25150 25724 24173>,
			<13606 14154 20250 25842 25554 24247>,
			<13583 14422 18990 27400 24326 23686>,
			<13567 14622 18604 28155 23350 23092>,
			<13564 14675 20110 25775 21977 22537>,
			<13557 14692 21589 22190 20659 21921>,
			<13495 14658 21424 20290 20357 21038>,
			<13290 14559 20385 19048 20234 20105>,
			<13273 14442 17207 19929 21097 19877>,
			<13454 14230 14884 21379 21823 20463>,
			<13594 14076 14802 20414 21434 23743>,
			<13906 14213 14731 19415 19020 19567>,
			<14106 14037 14567 19829 20206 19035>,
			<14202 14522 14518 19097 19654 21079>,
			<14488 15223 15012 19390 20333 22122>,
			<14733 16540 16351 19830 22687 20118>,
			<14746 16715 16363 21106 18879 23067>,
			<14250 15971 15066 21584 24759 22797>,
			<13783 14449 14539 21715 27433 27288>,
			<13344 13957 14230 23661 27080 28785>,
			<13344 13957 14230 23661 27080 28785>,
			<13344 13957 14230 23661 27080 28785>;
	};

	qcom,pc-temp-y6-lut {
		qcom,lut-col-legend = <(-10) 0 10 25 40 50>;
		qcom,lut-row-legend = <10000 9800 9600 9400 9200 9000>,
			<8800 8600 8400 8200 8000 7800>,
			<7600 7400 7200 7000 6800 6600>,
			<6400 6200 6000 5800 5600 5400>,
			<5200 5000 4800 4600 4400 4200>,
			<4000 3800 3600 3400 3200 3000>,
			<2800 2600 2400 2200 2000 1800>,
			<1600 1400 1200 1000 900 800>,
			<700 600 500 400 300 200>,
			<100 0>;
		qcom,lut-data = <6148 5490 5196 5046 5017 5011>,
			<6118 5490 5197 5046 5016 5011>,
			<6090 5488 5197 5045 5016 5011>,
			<6064 5484 5196 5045 5016 5011>,
			<6041 5481 5194 5045 5017 5012>,
			<6020 5477 5193 5045 5017 5012>,
			<6002 5474 5190 5046 5018 5012>,
			<5985 5470 5187 5047 5018 5013>,
			<5969 5463 5186 5048 5019 5014>,
			<5951 5453 5187 5050 5020 5015>,
			<5944 5449 5187 5051 5021 5015>,
			<5958 5478 5188 5053 5022 5016>,
			<5974 5514 5189 5055 5024 5017>,
			<5939 5503 5198 5058 5026 5019>,
			<5813 5452 5218 5063 5028 5020>,
			<5751 5418 5224 5067 5030 5022>,
			<5748 5403 5201 5069 5033 5024>,
			<5745 5392 5176 5072 5036 5026>,
			<5739 5383 5168 5077 5041 5030>,
			<5729 5377 5164 5083 5047 5035>,
			<5720 5368 5157 5083 5047 5035>,
			<5712 5356 5144 5063 5033 5024>,
			<5707 5344 5134 5044 5020 5015>,
			<5711 5336 5130 5041 5017 5013>,
			<5723 5328 5127 5039 5016 5012>,
			<5736 5327 5127 5039 5015 5012>,
			<5750 5332 5127 5040 5016 5012>,
			<5765 5341 5128 5041 5017 5013>,
			<5783 5353 5129 5043 5018 5014>,
			<5803 5368 5131 5045 5020 5016>,
			<5825 5383 5131 5047 5023 5017>,
			<5847 5399 5130 5049 5026 5019>,
			<5871 5417 5130 5051 5028 5021>,
			<5895 5439 5134 5051 5030 5023>,
			<5920 5465 5142 5052 5030 5025>,
			<5947 5491 5149 5052 5029 5023>,
			<5975 5519 5157 5051 5022 5017>,
			<6005 5550 5166 5050 5019 5014>,
			<6035 5584 5177 5048 5018 5013>,
			<6067 5621 5190 5047 5018 5013>,
			<6100 5661 5204 5047 5018 5013>,
			<6134 5703 5218 5050 5019 5014>,
			<6173 5750 5230 5054 5020 5015>,
			<6215 5802 5246 5057 5020 5014>,
			<6247 5847 5260 5055 5017 5012>,
			<6245 5869 5285 5060 5021 5015>,
			<6281 5908 5307 5066 5024 5017>,
			<6321 5955 5334 5072 5027 5021>,
			<6369 5998 5363 5082 5032 5025>,
			<6414 6040 5391 5086 5029 5020>,
			<6461 6067 5402 5082 5023 5017>,
			<6509 6102 5418 5084 5026 5018>,
			<6581 6167 5477 5097 5031 5022>,
			<6703 6274 5557 5118 5042 5032>,
			<6703 6274 5557 5118 5042 5032>,
			<6703 6274 5557 5118 5042 5032>;
	};

};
